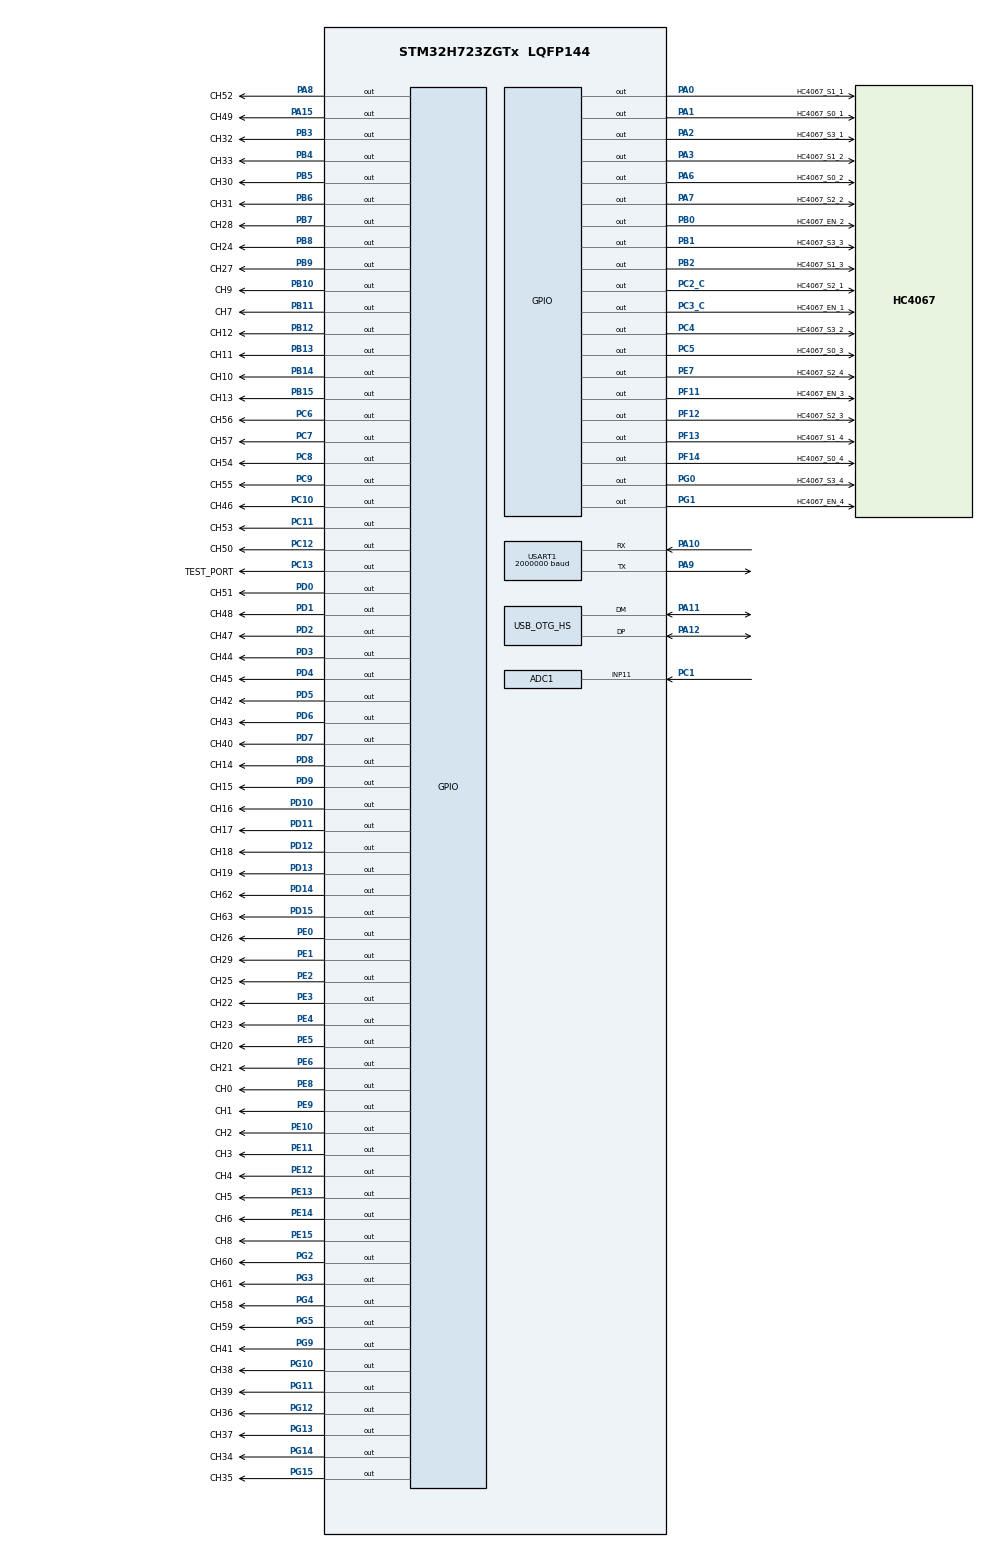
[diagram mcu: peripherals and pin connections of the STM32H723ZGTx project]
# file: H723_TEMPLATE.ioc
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ADC1.Channel-0\#ChannelRegularConversion=ADC_CHANNEL_11
ADC1.ContinuousConvMode=ENABLE
ADC1.ConversionDataManagement=ADC_CONVERSIONDATA_DMA_ONESHOT
ADC1.NbrOfConversionFlag=1
ADC1.OffsetNumber-0\#ChannelRegularConversion=ADC_OFFSET_NONE
ADC1.OffsetSignedSaturation-0\#ChannelRegularConversion=DISABLE
ADC1.Rank-0\#ChannelRegularConversion=1
ADC1.Resolution=ADC_RESOLUTION_8B
ADC1.SamplingTime-0\#ChannelRegularConversion=ADC_SAMPLETIME_1CYCLE_5
ADC1.master=1
CORTEX_M7.default_mode_Activation=1
Dma.ADC1.2.Direction=DMA_PERIPH_TO_MEMORY
Dma.ADC1.2.EventEnable=DISABLE
Dma.ADC1.2.FIFOMode=DMA_FIFOMODE_DISABLE
Dma.ADC1.2.Instance=DMA1_Stream1
Dma.ADC1.2.MemDataAlignment=DMA_MDATAALIGN_BYTE
Dma.ADC1.2.MemInc=DMA_MINC_ENABLE
Dma.ADC1.2.Mode=DMA_NORMAL
Dma.ADC1.2.PeriphDataAlignment=DMA_PDATAALIGN_BYTE
Dma.ADC1.2.PeriphInc=DMA_PINC_DISABLE
Dma.ADC1.2.Polarity=HAL_DMAMUX_REQ_GEN_RISING
Dma.ADC1.2.Priority=DMA_PRIORITY_LOW
Dma.ADC1.2.RequestNumber=1
Dma.ADC1.2.SignalID=NONE
Dma.ADC1.2.SyncEnable=DISABLE
Dma.ADC1.2.SyncPolarity=HAL_DMAMUX_SYNC_NO_EVENT
Dma.ADC1.2.SyncRequestNumber=1
Dma.ADC1.2.SyncSignalID=NONE
Dma.Request0=USART1_RX
Dma.Request1=USART1_TX
Dma.Request2=ADC1
Dma.USART1_RX.0.Direction=DMA_PERIPH_TO_MEMORY
Dma.USART1_RX.0.EventEnable=DISABLE
Dma.USART1_RX.0.FIFOMode=DMA_FIFOMODE_DISABLE
Dma.USART1_RX.0.Instance=DMA1_Stream0
Dma.USART1_RX.0.MemDataAlignment=DMA_MDATAALIGN_BYTE
Dma.USART1_RX.0.MemInc=DMA_MINC_ENABLE
Dma.USART1_RX.0.Mode=DMA_NORMAL
Dma.USART1_RX.0.PeriphDataAlignment=DMA_PDATAALIGN_BYTE
Dma.USART1_RX.0.PeriphInc=DMA_PINC_DISABLE
Dma.USART1_RX.0.Polarity=HAL_DMAMUX_REQ_GEN_RISING
Dma.USART1_RX.0.Priority=DMA_PRIORITY_LOW
Dma.USART1_RX.0.RequestNumber=1
Dma.USART1_RX.0.SignalID=NONE
Dma.USART1_RX.0.SyncEnable=DISABLE
Dma.USART1_RX.0.SyncPolarity=HAL_DMAMUX_SYNC_NO_EVENT
Dma.USART1_RX.0.SyncRequestNumber=1
Dma.USART1_RX.0.SyncSignalID=NONE
Dma.USART1_TX.1.Direction=DMA_MEMORY_TO_PERIPH
Dma.USART1_TX.1.EventEnable=DISABLE
Dma.USART1_TX.1.FIFOMode=DMA_FIFOMODE_DISABLE
Dma.USART1_TX.1.Instance=DMA2_Stream7
Dma.USART1_TX.1.MemDataAlignment=DMA_MDATAALIGN_BYTE
Dma.USART1_TX.1.MemInc=DMA_MINC_ENABLE
Dma.USART1_TX.1.Mode=DMA_NORMAL
Dma.USART1_TX.1.PeriphDataAlignment=DMA_PDATAALIGN_BYTE
Dma.USART1_TX.1.PeriphInc=DMA_PINC_DISABLE
Dma.USART1_TX.1.Polarity=HAL_DMAMUX_REQ_GEN_RISING
Dma.USART1_TX.1.Priority=DMA_PRIORITY_MEDIUM
Dma.USART1_TX.1.RequestNumber=1
Dma.USART1_TX.1.SignalID=NONE
Dma.USART1_TX.1.SyncEnable=DISABLE
Dma.USART1_TX.1.SyncPolarity=HAL_DMAMUX_SYNC_NO_EVENT
Dma.USART1_TX.1.SyncRequestNumber=1
Dma.USART1_TX.1.SyncSignalID=NONE
Mcu.Family=STM32H7
Mcu.Name=STM32H723ZGTx
Mcu.Package=LQFP144
NVIC.DMA1_Stream0_IRQn=true\:0\:0\:false\:false\:true\:false\:true\:true
NVIC.DMA1_Stream1_IRQn=true\:0\:0\:false\:false\:true\:false\:true\:true
NVIC.DMA2_Stream7_IRQn=true\:0\:0\:false\:false\:true\:false\:true\:true
NVIC.OTG_HS_IRQn=true\:0\:0\:false\:false\:true\:false\:true\:true
NVIC.PriorityGroup=NVIC_PRIORITYGROUP_4
NVIC.USART1_IRQn=true\:0\:0\:false\:false\:true\:false\:true\:true
PA0.GPIO_Label=HC4067_S1_1
PA0.GPIO_ModeDefaultOutputPP=GPIO_MODE_OUTPUT_PP
PA0.GPIO_PuPd=GPIO_NOPULL
PA0.GPIO_Speed=GPIO_SPEED_FREQ_VERY_HIGH
PA0.PinState=GPIO_PIN_SET
PA0.Signal=GPIO_Output
PA1.GPIO_Label=HC4067_S0_1
PA1.GPIO_ModeDefaultOutputPP=GPIO_MODE_OUTPUT_PP
PA1.GPIO_PuPd=GPIO_NOPULL
PA1.GPIO_Speed=GPIO_SPEED_FREQ_VERY_HIGH
PA1.PinState=GPIO_PIN_SET
PA1.Signal=GPIO_Output
PA10.Mode=Asynchronous
PA10.Signal=USART1_RX
PA11.Mode=Device_Only_FS
PA11.Signal=USB_OTG_HS_DM
PA12.Mode=Device_Only_FS
PA12.Signal=USB_OTG_HS_DP
PA13(JTMS/SWDIO).Mode=Serial_Wire
PA13(JTMS/SWDIO).Signal=DEBUG_JTMS-SWDIO
PA14(JTCK/SWCLK).Mode=Serial_Wire
PA14(JTCK/SWCLK).Signal=DEBUG_JTCK-SWCLK
PA15(JTDI).GPIO_Label=CH49
PA15(JTDI).GPIO_ModeDefaultOutputPP=GPIO_MODE_OUTPUT_PP
PA15(JTDI).GPIO_PuPd=GPIO_NOPULL
PA15(JTDI).GPIO_Speed=GPIO_SPEED_FREQ_VERY_HIGH
PA15(JTDI).PinState=GPIO_PIN_RESET
PA15(JTDI).Signal=GPIO_Output
PA2.GPIO_Label=HC4067_S3_1
PA2.GPIO_ModeDefaultOutputPP=GPIO_MODE_OUTPUT_PP
PA2.GPIO_PuPd=GPIO_NOPULL
PA2.GPIO_Speed=GPIO_SPEED_FREQ_VERY_HIGH
PA2.PinState=GPIO_PIN_SET
PA2.Signal=GPIO_Output
PA3.GPIO_Label=HC4067_S1_2
PA3.GPIO_ModeDefaultOutputPP=GPIO_MODE_OUTPUT_PP
PA3.GPIO_PuPd=GPIO_NOPULL
PA3.GPIO_Speed=GPIO_SPEED_FREQ_VERY_HIGH
PA3.PinState=GPIO_PIN_SET
PA3.Signal=GPIO_Output
PA6.GPIO_Label=HC4067_S0_2
PA6.GPIO_ModeDefaultOutputPP=GPIO_MODE_OUTPUT_PP
PA6.GPIO_PuPd=GPIO_NOPULL
PA6.GPIO_Speed=GPIO_SPEED_FREQ_VERY_HIGH
PA6.PinState=GPIO_PIN_SET
PA6.Signal=GPIO_Output
PA7.GPIO_Label=HC4067_S2_2
PA7.GPIO_ModeDefaultOutputPP=GPIO_MODE_OUTPUT_PP
PA7.GPIO_PuPd=GPIO_NOPULL
PA7.GPIO_Speed=GPIO_SPEED_FREQ_VERY_HIGH
PA7.PinState=GPIO_PIN_SET
PA7.Signal=GPIO_Output
PA8.GPIO_Label=CH52
PA8.GPIO_ModeDefaultOutputPP=GPIO_MODE_OUTPUT_PP
PA8.GPIO_PuPd=GPIO_NOPULL
PA8.GPIO_Speed=GPIO_SPEED_FREQ_VERY_HIGH
PA8.PinState=GPIO_PIN_RESET
PA8.Signal=GPIO_Output
PA9.Mode=Asynchronous
PA9.Signal=USART1_TX
PB0.GPIO_Label=HC4067_EN_2
PB0.GPIO_ModeDefaultOutputPP=GPIO_MODE_OUTPUT_PP
PB0.GPIO_PuPd=GPIO_NOPULL
PB0.GPIO_Speed=GPIO_SPEED_FREQ_VERY_HIGH
PB0.PinState=GPIO_PIN_SET
PB0.Signal=GPIO_Output
PB1.GPIO_Label=HC4067_S3_3
PB1.GPIO_ModeDefaultOutputPP=GPIO_MODE_OUTPUT_PP
PB1.GPIO_PuPd=GPIO_NOPULL
PB1.GPIO_Speed=GPIO_SPEED_FREQ_VERY_HIGH
PB1.PinState=GPIO_PIN_SET
PB1.Signal=GPIO_Output
PB10.GPIO_Label=CH9
PB10.GPIO_ModeDefaultOutputPP=GPIO_MODE_OUTPUT_PP
PB10.GPIO_PuPd=GPIO_NOPULL
PB10.GPIO_Speed=GPIO_SPEED_FREQ_VERY_HIGH
PB10.PinState=GPIO_PIN_RESET
PB10.Signal=GPIO_Output
PB11.GPIO_Label=CH7
PB11.GPIO_ModeDefaultOutputPP=GPIO_MODE_OUTPUT_PP
PB11.GPIO_PuPd=GPIO_NOPULL
PB11.GPIO_Speed=GPIO_SPEED_FREQ_VERY_HIGH
PB11.PinState=GPIO_PIN_RESET
PB11.Signal=GPIO_Output
PB12.GPIO_Label=CH12
PB12.GPIO_ModeDefaultOutputPP=GPIO_MODE_OUTPUT_PP
PB12.GPIO_PuPd=GPIO_NOPULL
PB12.GPIO_Speed=GPIO_SPEED_FREQ_VERY_HIGH
PB12.PinState=GPIO_PIN_RESET
PB12.Signal=GPIO_Output
PB13.GPIO_Label=CH11
PB13.GPIO_ModeDefaultOutputPP=GPIO_MODE_OUTPUT_PP
PB13.GPIO_PuPd=GPIO_NOPULL
PB13.GPIO_Speed=GPIO_SPEED_FREQ_VERY_HIGH
PB13.PinState=GPIO_PIN_RESET
PB13.Signal=GPIO_Output
PB14.GPIO_Label=CH10
PB14.GPIO_ModeDefaultOutputPP=GPIO_MODE_OUTPUT_PP
PB14.GPIO_PuPd=GPIO_NOPULL
PB14.GPIO_Speed=GPIO_SPEED_FREQ_VERY_HIGH
PB14.PinState=GPIO_PIN_RESET
PB14.Signal=GPIO_Output
PB15.GPIO_Label=CH13
PB15.GPIO_ModeDefaultOutputPP=GPIO_MODE_OUTPUT_PP
PB15.GPIO_PuPd=GPIO_NOPULL
PB15.GPIO_Speed=GPIO_SPEED_FREQ_VERY_HIGH
PB15.PinState=GPIO_PIN_RESET
PB15.Signal=GPIO_Output
PB2.GPIO_Label=HC4067_S1_3
PB2.GPIO_ModeDefaultOutputPP=GPIO_MODE_OUTPUT_PP
PB2.GPIO_PuPd=GPIO_NOPULL
PB2.GPIO_Speed=GPIO_SPEED_FREQ_VERY_HIGH
PB2.PinState=GPIO_PIN_SET
PB2.Signal=GPIO_Output
PB3(JTDO/TRACESWO).GPIO_Label=CH32
PB3(JTDO/TRACESWO).GPIO_ModeDefaultOutputPP=GPIO_MODE_OUTPUT_PP
PB3(JTDO/TRACESWO).GPIO_PuPd=GPIO_NOPULL
PB3(JTDO/TRACESWO).GPIO_Speed=GPIO_SPEED_FREQ_VERY_HIGH
PB3(JTDO/TRACESWO).PinState=GPIO_PIN_RESET
PB3(JTDO/TRACESWO).Signal=GPIO_Output
PB4(NJTRST).GPIO_Label=CH33
PB4(NJTRST).GPIO_ModeDefaultOutputPP=GPIO_MODE_OUTPUT_PP
PB4(NJTRST).GPIO_PuPd=GPIO_NOPULL
PB4(NJTRST).GPIO_Speed=GPIO_SPEED_FREQ_VERY_HIGH
PB4(NJTRST).PinState=GPIO_PIN_RESET
PB4(NJTRST).Signal=GPIO_Output
PB5.GPIO_Label=CH30
PB5.GPIO_ModeDefaultOutputPP=GPIO_MODE_OUTPUT_PP
PB5.GPIO_PuPd=GPIO_NOPULL
PB5.GPIO_Speed=GPIO_SPEED_FREQ_VERY_HIGH
PB5.PinState=GPIO_PIN_RESET
PB5.Signal=GPIO_Output
PB6.GPIO_Label=CH31
PB6.GPIO_ModeDefaultOutputPP=GPIO_MODE_OUTPUT_PP
PB6.GPIO_PuPd=GPIO_NOPULL
PB6.GPIO_Speed=GPIO_SPEED_FREQ_VERY_HIGH
PB6.PinState=GPIO_PIN_RESET
PB6.Signal=GPIO_Output
PB7.GPIO_Label=CH28
PB7.GPIO_ModeDefaultOutputPP=GPIO_MODE_OUTPUT_PP
PB7.GPIO_PuPd=GPIO_NOPULL
PB7.GPIO_Speed=GPIO_SPEED_FREQ_VERY_HIGH
PB7.PinState=GPIO_PIN_RESET
PB7.Signal=GPIO_Output
PB8.GPIO_Label=CH24
PB8.GPIO_ModeDefaultOutputPP=GPIO_MODE_OUTPUT_PP
PB8.GPIO_PuPd=GPIO_NOPULL
PB8.GPIO_Speed=GPIO_SPEED_FREQ_VERY_HIGH
PB8.PinState=GPIO_PIN_RESET
PB8.Signal=GPIO_Output
PB9.GPIO_Label=CH27
PB9.GPIO_ModeDefaultOutputPP=GPIO_MODE_OUTPUT_PP
PB9.GPIO_PuPd=GPIO_NOPULL
PB9.GPIO_Speed=GPIO_SPEED_FREQ_VERY_HIGH
PB9.PinState=GPIO_PIN_RESET
PB9.Signal=GPIO_Output
PC1.Signal=ADCx_INP11
PC10.GPIO_Label=CH46
PC10.GPIO_ModeDefaultOutputPP=GPIO_MODE_OUTPUT_PP
PC10.GPIO_PuPd=GPIO_NOPULL
PC10.GPIO_Speed=GPIO_SPEED_FREQ_VERY_HIGH
PC10.PinState=GPIO_PIN_RESET
PC10.Signal=GPIO_Output
PC11.GPIO_Label=CH53
PC11.GPIO_ModeDefaultOutputPP=GPIO_MODE_OUTPUT_PP
PC11.GPIO_PuPd=GPIO_NOPULL
PC11.GPIO_Speed=GPIO_SPEED_FREQ_VERY_HIGH
PC11.PinState=GPIO_PIN_RESET
PC11.Signal=GPIO_Output
PC12.GPIO_Label=CH50
PC12.GPIO_ModeDefaultOutputPP=GPIO_MODE_OUTPUT_PP
PC12.GPIO_PuPd=GPIO_NOPULL
PC12.GPIO_Speed=GPIO_SPEED_FREQ_VERY_HIGH
PC12.PinState=GPIO_PIN_RESET
PC12.Signal=GPIO_Output
PC13.GPIO_Label=TEST_PORT
PC13.Signal=GPIO_Output
PC2_C.GPIO_Label=HC4067_S2_1
PC2_C.GPIO_ModeDefaultOutputPP=GPIO_MODE_OUTPUT_PP
PC2_C.GPIO_PuPd=GPIO_NOPULL
PC2_C.GPIO_Speed=GPIO_SPEED_FREQ_VERY_HIGH
PC2_C.PinState=GPIO_PIN_SET
PC2_C.Signal=GPIO_Output
PC3_C.GPIO_Label=HC4067_EN_1
PC3_C.GPIO_ModeDefaultOutputPP=GPIO_MODE_OUTPUT_PP
PC3_C.GPIO_PuPd=GPIO_NOPULL
PC3_C.GPIO_Speed=GPIO_SPEED_FREQ_VERY_HIGH
PC3_C.PinState=GPIO_PIN_SET
PC3_C.Signal=GPIO_Output
PC4.GPIO_Label=HC4067_S3_2
PC4.GPIO_ModeDefaultOutputPP=GPIO_MODE_OUTPUT_PP
PC4.GPIO_PuPd=GPIO_NOPULL
PC4.GPIO_Speed=GPIO_SPEED_FREQ_VERY_HIGH
PC4.PinState=GPIO_PIN_SET
PC4.Signal=GPIO_Output
PC5.GPIO_Label=HC4067_S0_3
PC5.GPIO_ModeDefaultOutputPP=GPIO_MODE_OUTPUT_PP
PC5.GPIO_PuPd=GPIO_NOPULL
PC5.GPIO_Speed=GPIO_SPEED_FREQ_VERY_HIGH
PC5.PinState=GPIO_PIN_SET
PC5.Signal=GPIO_Output
PC6.GPIO_Label=CH56
PC6.GPIO_ModeDefaultOutputPP=GPIO_MODE_OUTPUT_PP
PC6.GPIO_PuPd=GPIO_NOPULL
PC6.GPIO_Speed=GPIO_SPEED_FREQ_VERY_HIGH
PC6.PinState=GPIO_PIN_RESET
PC6.Signal=GPIO_Output
PC7.GPIO_Label=CH57
PC7.GPIO_ModeDefaultOutputPP=GPIO_MODE_OUTPUT_PP
PC7.GPIO_PuPd=GPIO_NOPULL
PC7.GPIO_Speed=GPIO_SPEED_FREQ_VERY_HIGH
PC7.PinState=GPIO_PIN_RESET
PC7.Signal=GPIO_Output
PC8.GPIO_Label=CH54
PC8.GPIO_ModeDefaultOutputPP=GPIO_MODE_OUTPUT_PP
PC8.GPIO_PuPd=GPIO_NOPULL
PC8.GPIO_Speed=GPIO_SPEED_FREQ_VERY_HIGH
PC8.PinState=GPIO_PIN_RESET
PC8.Signal=GPIO_Output
PC9.GPIO_Label=CH55
PC9.GPIO_ModeDefaultOutputPP=GPIO_MODE_OUTPUT_PP
PC9.GPIO_PuPd=GPIO_NOPULL
PC9.GPIO_Speed=GPIO_SPEED_FREQ_VERY_HIGH
PC9.PinState=GPIO_PIN_RESET
PC9.Signal=GPIO_Output
PD0.GPIO_Label=CH51
PD0.GPIO_ModeDefaultOutputPP=GPIO_MODE_OUTPUT_PP
PD0.GPIO_PuPd=GPIO_NOPULL
PD0.GPIO_Speed=GPIO_SPEED_FREQ_VERY_HIGH
PD0.PinState=GPIO_PIN_RESET
PD0.Signal=GPIO_Output
PD1.GPIO_Label=CH48
PD1.GPIO_ModeDefaultOutputPP=GPIO_MODE_OUTPUT_PP
PD1.GPIO_PuPd=GPIO_NOPULL
PD1.GPIO_Speed=GPIO_SPEED_FREQ_VERY_HIGH
PD1.PinState=GPIO_PIN_RESET
PD1.Signal=GPIO_Output
PD10.GPIO_Label=CH16
PD10.GPIO_ModeDefaultOutputPP=GPIO_MODE_OUTPUT_PP
PD10.GPIO_PuPd=GPIO_NOPULL
PD10.GPIO_Speed=GPIO_SPEED_FREQ_VERY_HIGH
PD10.PinState=GPIO_PIN_RESET
PD10.Signal=GPIO_Output
PD11.GPIO_Label=CH17
PD11.GPIO_ModeDefaultOutputPP=GPIO_MODE_OUTPUT_PP
PD11.GPIO_PuPd=GPIO_NOPULL
PD11.GPIO_Speed=GPIO_SPEED_FREQ_VERY_HIGH
PD11.PinState=GPIO_PIN_RESET
PD11.Signal=GPIO_Output
PD12.GPIO_Label=CH18
PD12.GPIO_ModeDefaultOutputPP=GPIO_MODE_OUTPUT_PP
PD12.GPIO_PuPd=GPIO_NOPULL
PD12.GPIO_Speed=GPIO_SPEED_FREQ_VERY_HIGH
PD12.PinState=GPIO_PIN_RESET
PD12.Signal=GPIO_Output
PD13.GPIO_Label=CH19
PD13.GPIO_ModeDefaultOutputPP=GPIO_MODE_OUTPUT_PP
PD13.GPIO_PuPd=GPIO_NOPULL
PD13.GPIO_Speed=GPIO_SPEED_FREQ_VERY_HIGH
PD13.PinState=GPIO_PIN_RESET
PD13.Signal=GPIO_Output
PD14.GPIO_Label=CH62
PD14.GPIO_ModeDefaultOutputPP=GPIO_MODE_OUTPUT_PP
PD14.GPIO_PuPd=GPIO_NOPULL
PD14.GPIO_Speed=GPIO_SPEED_FREQ_VERY_HIGH
PD14.PinState=GPIO_PIN_RESET
PD14.Signal=GPIO_Output
PD15.GPIO_Label=CH63
PD15.GPIO_ModeDefaultOutputPP=GPIO_MODE_OUTPUT_PP
PD15.GPIO_PuPd=GPIO_NOPULL
PD15.GPIO_Speed=GPIO_SPEED_FREQ_VERY_HIGH
PD15.PinState=GPIO_PIN_RESET
PD15.Signal=GPIO_Output
PD2.GPIO_Label=CH47
PD2.GPIO_ModeDefaultOutputPP=GPIO_MODE_OUTPUT_PP
PD2.GPIO_PuPd=GPIO_NOPULL
PD2.GPIO_Speed=GPIO_SPEED_FREQ_VERY_HIGH
PD2.PinState=GPIO_PIN_RESET
PD2.Signal=GPIO_Output
PD3.GPIO_Label=CH44
PD3.GPIO_ModeDefaultOutputPP=GPIO_MODE_OUTPUT_PP
PD3.GPIO_PuPd=GPIO_NOPULL
PD3.GPIO_Speed=GPIO_SPEED_FREQ_VERY_HIGH
PD3.PinState=GPIO_PIN_RESET
PD3.Signal=GPIO_Output
PD4.GPIO_Label=CH45
PD4.GPIO_ModeDefaultOutputPP=GPIO_MODE_OUTPUT_PP
PD4.GPIO_PuPd=GPIO_NOPULL
PD4.GPIO_Speed=GPIO_SPEED_FREQ_VERY_HIGH
PD4.PinState=GPIO_PIN_RESET
PD4.Signal=GPIO_Output
PD5.GPIO_Label=CH42
PD5.GPIO_ModeDefaultOutputPP=GPIO_MODE_OUTPUT_PP
PD5.GPIO_PuPd=GPIO_NOPULL
PD5.GPIO_Speed=GPIO_SPEED_FREQ_VERY_HIGH
PD5.PinState=GPIO_PIN_RESET
PD5.Signal=GPIO_Output
PD6.GPIO_Label=CH43
PD6.GPIO_ModeDefaultOutputPP=GPIO_MODE_OUTPUT_PP
PD6.GPIO_PuPd=GPIO_NOPULL
PD6.GPIO_Speed=GPIO_SPEED_FREQ_VERY_HIGH
PD6.PinState=GPIO_PIN_RESET
PD6.Signal=GPIO_Output
PD7.GPIO_Label=CH40
PD7.GPIO_ModeDefaultOutputPP=GPIO_MODE_OUTPUT_PP
PD7.GPIO_PuPd=GPIO_NOPULL
PD7.GPIO_Speed=GPIO_SPEED_FREQ_VERY_HIGH
PD7.PinState=GPIO_PIN_RESET
PD7.Signal=GPIO_Output
PD8.GPIO_Label=CH14
PD8.GPIO_ModeDefaultOutputPP=GPIO_MODE_OUTPUT_PP
PD8.GPIO_PuPd=GPIO_NOPULL
PD8.GPIO_Speed=GPIO_SPEED_FREQ_VERY_HIGH
PD8.PinState=GPIO_PIN_RESET
PD8.Signal=GPIO_Output
PD9.GPIO_Label=CH15
PD9.GPIO_ModeDefaultOutputPP=GPIO_MODE_OUTPUT_PP
PD9.GPIO_PuPd=GPIO_NOPULL
PD9.GPIO_Speed=GPIO_SPEED_FREQ_VERY_HIGH
PD9.PinState=GPIO_PIN_RESET
PD9.Signal=GPIO_Output
PE0.GPIO_Label=CH26
PE0.GPIO_ModeDefaultOutputPP=GPIO_MODE_OUTPUT_PP
PE0.GPIO_PuPd=GPIO_NOPULL
PE0.GPIO_Speed=GPIO_SPEED_FREQ_VERY_HIGH
PE0.PinState=GPIO_PIN_RESET
PE0.Signal=GPIO_Output
PE1.GPIO_Label=CH29
PE1.GPIO_ModeDefaultOutputPP=GPIO_MODE_OUTPUT_PP
PE1.GPIO_PuPd=GPIO_NOPULL
PE1.GPIO_Speed=GPIO_SPEED_FREQ_VERY_HIGH
PE1.PinState=GPIO_PIN_RESET
PE1.Signal=GPIO_Output
PE10.GPIO_Label=CH2
PE10.GPIO_ModeDefaultOutputPP=GPIO_MODE_OUTPUT_PP
PE10.GPIO_PuPd=GPIO_NOPULL
PE10.GPIO_Speed=GPIO_SPEED_FREQ_VERY_HIGH
PE10.PinState=GPIO_PIN_RESET
PE10.Signal=GPIO_Output
PE11.GPIO_Label=CH3
PE11.GPIO_ModeDefaultOutputPP=GPIO_MODE_OUTPUT_PP
PE11.GPIO_PuPd=GPIO_NOPULL
PE11.GPIO_Speed=GPIO_SPEED_FREQ_VERY_HIGH
PE11.PinState=GPIO_PIN_RESET
PE11.Signal=GPIO_Output
PE12.GPIO_Label=CH4
PE12.GPIO_ModeDefaultOutputPP=GPIO_MODE_OUTPUT_PP
PE12.GPIO_PuPd=GPIO_NOPULL
PE12.GPIO_Speed=GPIO_SPEED_FREQ_VERY_HIGH
PE12.PinState=GPIO_PIN_RESET
PE12.Signal=GPIO_Output
PE13.GPIO_Label=CH5
PE13.GPIO_ModeDefaultOutputPP=GPIO_MODE_OUTPUT_PP
PE13.GPIO_PuPd=GPIO_NOPULL
PE13.GPIO_Speed=GPIO_SPEED_FREQ_VERY_HIGH
PE13.PinState=GPIO_PIN_RESET
PE13.Signal=GPIO_Output
PE14.GPIO_Label=CH6
PE14.GPIO_ModeDefaultOutputPP=GPIO_MODE_OUTPUT_PP
PE14.GPIO_PuPd=GPIO_NOPULL
PE14.GPIO_Speed=GPIO_SPEED_FREQ_VERY_HIGH
PE14.PinState=GPIO_PIN_RESET
PE14.Signal=GPIO_Output
PE15.GPIO_Label=CH8
PE15.GPIO_ModeDefaultOutputPP=GPIO_MODE_OUTPUT_PP
PE15.GPIO_PuPd=GPIO_NOPULL
PE15.GPIO_Speed=GPIO_SPEED_FREQ_VERY_HIGH
PE15.PinState=GPIO_PIN_RESET
PE15.Signal=GPIO_Output
PE2.GPIO_Label=CH25
PE2.GPIO_Speed=GPIO_SPEED_FREQ_VERY_HIGH
PE2.Signal=GPIO_Output
PE3.GPIO_Label=CH22
PE3.GPIO_ModeDefaultOutputPP=GPIO_MODE_OUTPUT_PP
PE3.GPIO_PuPd=GPIO_NOPULL
PE3.GPIO_Speed=GPIO_SPEED_FREQ_VERY_HIGH
PE3.PinState=GPIO_PIN_RESET
PE3.Signal=GPIO_Output
PE4.GPIO_Label=CH23
PE4.GPIO_ModeDefaultOutputPP=GPIO_MODE_OUTPUT_PP
PE4.GPIO_PuPd=GPIO_NOPULL
PE4.GPIO_Speed=GPIO_SPEED_FREQ_VERY_HIGH
PE4.PinState=GPIO_PIN_RESET
PE4.Signal=GPIO_Output
PE5.GPIO_Label=CH20
PE5.GPIO_ModeDefaultOutputPP=GPIO_MODE_OUTPUT_PP
PE5.GPIO_PuPd=GPIO_NOPULL
PE5.GPIO_Speed=GPIO_SPEED_FREQ_VERY_HIGH
PE5.PinState=GPIO_PIN_RESET
PE5.Signal=GPIO_Output
PE6.GPIO_Label=CH21
PE6.GPIO_ModeDefaultOutputPP=GPIO_MODE_OUTPUT_PP
PE6.GPIO_PuPd=GPIO_NOPULL
PE6.GPIO_Speed=GPIO_SPEED_FREQ_VERY_HIGH
PE6.PinState=GPIO_PIN_RESET
PE6.Signal=GPIO_Output
PE7.GPIO_Label=HC4067_S2_4
PE7.GPIO_Speed=GPIO_SPEED_FREQ_VERY_HIGH
PE7.PinState=GPIO_PIN_SET
PE7.Signal=GPIO_Output
PE8.GPIO_Label=CH0
PE8.GPIO_ModeDefaultOutputPP=GPIO_MODE_OUTPUT_PP
PE8.GPIO_PuPd=GPIO_NOPULL
PE8.GPIO_Speed=GPIO_SPEED_FREQ_VERY_HIGH
PE8.PinState=GPIO_PIN_RESET
PE8.Signal=GPIO_Output
PE9.GPIO_Label=CH1
PE9.GPIO_ModeDefaultOutputPP=GPIO_MODE_OUTPUT_PP
PE9.GPIO_PuPd=GPIO_NOPULL
PE9.GPIO_Speed=GPIO_SPEED_FREQ_VERY_HIGH
PE9.PinState=GPIO_PIN_RESET
PE9.Signal=GPIO_Output
PF11.GPIO_Label=HC4067_EN_3
PF11.GPIO_ModeDefaultOutputPP=GPIO_MODE_OUTPUT_PP
PF11.GPIO_PuPd=GPIO_NOPULL
PF11.GPIO_Speed=GPIO_SPEED_FREQ_VERY_HIGH
PF11.PinState=GPIO_PIN_SET
PF11.Signal=GPIO_Output
PF12.GPIO_Label=HC4067_S2_3
PF12.GPIO_ModeDefaultOutputPP=GPIO_MODE_OUTPUT_PP
PF12.GPIO_PuPd=GPIO_NOPULL
PF12.GPIO_Speed=GPIO_SPEED_FREQ_VERY_HIGH
PF12.PinState=GPIO_PIN_SET
PF12.Signal=GPIO_Output
PF13.GPIO_Label=HC4067_S1_4
PF13.GPIO_ModeDefaultOutputPP=GPIO_MODE_OUTPUT_PP
PF13.GPIO_PuPd=GPIO_NOPULL
PF13.GPIO_Speed=GPIO_SPEED_FREQ_VERY_HIGH
PF13.PinState=GPIO_PIN_SET
PF13.Signal=GPIO_Output
PF14.GPIO_Label=HC4067_S0_4
PF14.GPIO_ModeDefaultOutputPP=GPIO_MODE_OUTPUT_PP
PF14.GPIO_PuPd=GPIO_NOPULL
PF14.GPIO_Speed=GPIO_SPEED_FREQ_VERY_HIGH
PF14.PinState=GPIO_PIN_SET
PF14.Signal=GPIO_Output
PG0.GPIO_Label=HC4067_S3_4
PG0.GPIO_ModeDefaultOutputPP=GPIO_MODE_OUTPUT_PP
PG0.GPIO_PuPd=GPIO_NOPULL
PG0.GPIO_Speed=GPIO_SPEED_FREQ_VERY_HIGH
PG0.PinState=GPIO_PIN_SET
PG0.Signal=GPIO_Output
PG1.GPIO_Label=HC4067_EN_4
PG1.GPIO_ModeDefaultOutputPP=GPIO_MODE_OUTPUT_PP
PG1.GPIO_PuPd=GPIO_NOPULL
PG1.GPIO_Speed=GPIO_SPEED_FREQ_VERY_HIGH
PG1.PinState=GPIO_PIN_SET
PG1.Signal=GPIO_Output
PG10.GPIO_Label=CH38
PG10.GPIO_ModeDefaultOutputPP=GPIO_MODE_OUTPUT_PP
PG10.GPIO_PuPd=GPIO_NOPULL
PG10.GPIO_Speed=GPIO_SPEED_FREQ_VERY_HIGH
PG10.PinState=GPIO_PIN_RESET
PG10.Signal=GPIO_Output
PG11.GPIO_Label=CH39
PG11.GPIO_ModeDefaultOutputPP=GPIO_MODE_OUTPUT_PP
PG11.GPIO_PuPd=GPIO_NOPULL
PG11.GPIO_Speed=GPIO_SPEED_FREQ_VERY_HIGH
PG11.PinState=GPIO_PIN_RESET
PG11.Signal=GPIO_Output
PG12.GPIO_Label=CH36
PG12.GPIO_ModeDefaultOutputPP=GPIO_MODE_OUTPUT_PP
PG12.GPIO_PuPd=GPIO_NOPULL
PG12.GPIO_Speed=GPIO_SPEED_FREQ_VERY_HIGH
PG12.PinState=GPIO_PIN_RESET
PG12.Signal=GPIO_Output
PG13.GPIO_Label=CH37
PG13.GPIO_ModeDefaultOutputPP=GPIO_MODE_OUTPUT_PP
PG13.GPIO_PuPd=GPIO_NOPULL
PG13.GPIO_Speed=GPIO_SPEED_FREQ_VERY_HIGH
PG13.PinState=GPIO_PIN_RESET
PG13.Signal=GPIO_Output
PG14.GPIO_Label=CH34
PG14.GPIO_ModeDefaultOutputPP=GPIO_MODE_OUTPUT_PP
PG14.GPIO_PuPd=GPIO_NOPULL
PG14.GPIO_Speed=GPIO_SPEED_FREQ_VERY_HIGH
PG14.PinState=GPIO_PIN_RESET
PG14.Signal=GPIO_Output
PG15.GPIO_Label=CH35
PG15.GPIO_ModeDefaultOutputPP=GPIO_MODE_OUTPUT_PP
PG15.GPIO_PuPd=GPIO_NOPULL
PG15.GPIO_Speed=GPIO_SPEED_FREQ_VERY_HIGH
PG15.PinState=GPIO_PIN_RESET
PG15.Signal=GPIO_Output
PG2.GPIO_Label=CH60
PG2.GPIO_ModeDefaultOutputPP=GPIO_MODE_OUTPUT_PP
PG2.GPIO_PuPd=GPIO_NOPULL
PG2.GPIO_Speed=GPIO_SPEED_FREQ_VERY_HIGH
PG2.PinState=GPIO_PIN_RESET
PG2.Signal=GPIO_Output
PG3.GPIO_Label=CH61
PG3.GPIO_ModeDefaultOutputPP=GPIO_MODE_OUTPUT_PP
PG3.GPIO_PuPd=GPIO_NOPULL
PG3.GPIO_Speed=GPIO_SPEED_FREQ_VERY_HIGH
PG3.PinState=GPIO_PIN_RESET
PG3.Signal=GPIO_Output
PG4.GPIO_Label=CH58
PG4.GPIO_ModeDefaultOutputPP=GPIO_MODE_OUTPUT_PP
PG4.GPIO_PuPd=GPIO_NOPULL
PG4.GPIO_Speed=GPIO_SPEED_FREQ_VERY_HIGH
PG4.PinState=GPIO_PIN_RESET
PG4.Signal=GPIO_Output
PG5.GPIO_Label=CH59
PG5.GPIO_ModeDefaultOutputPP=GPIO_MODE_OUTPUT_PP
PG5.GPIO_PuPd=GPIO_NOPULL
PG5.GPIO_Speed=GPIO_SPEED_FREQ_VERY_HIGH
PG5.PinState=GPIO_PIN_RESET
PG5.Signal=GPIO_Output
PG9.GPIO_Label=CH41
PG9.GPIO_ModeDefaultOutputPP=GPIO_MODE_OUTPUT_PP
PG9.GPIO_PuPd=GPIO_NOPULL
PG9.GPIO_Speed=GPIO_SPEED_FREQ_VERY_HIGH
PG9.PinState=GPIO_PIN_RESET
PG9.Signal=GPIO_Output
PH0-OSC_IN.Mode=HSE-External-Oscillator
PH0-OSC_IN.Signal=RCC_OSC_IN
PH1-OSC_OUT.Mode=HSE-External-Oscillator
PH1-OSC_OUT.Signal=RCC_OSC_OUT
ProjectManager.HeapSize=0x200
ProjectManager.StackSize=0x400
ProjectManager.TargetToolchain=MDK-ARM V5.32
RCC.ADCCLockSelection=RCC_ADCCLKSOURCE_PLL3
RCC.ADCFreq_Value=120000000
RCC.APB1Freq_Value=137500000
RCC.APB2Freq_Value=137500000
RCC.APB3Freq_Value=137500000
RCC.APB4Freq_Value=137500000
RCC.CortexFreq_Value=550000000
RCC.D1PPRE=RCC_APB3_DIV2
RCC.D2PPRE1=RCC_APB1_DIV2
RCC.D2PPRE2=RCC_APB2_DIV2
RCC.D3PPRE=RCC_APB4_DIV2
RCC.DIVM1=2
RCC.DIVM2=2
RCC.DIVM3=5
RCC.DIVN1=44
RCC.DIVN2=15
RCC.DIVN3=48
RCC.DIVP1=1
RCC.DIVQ3=5
RCC.HCLKFreq_Value=275000000
RCC.HPRE=RCC_HCLK_DIV2
RCC.PLL2FRACN=0
RCC.PLL3FRACN=0
RCC.PLLFRACN=0
RCC.SYSCLKFreq_VALUE=550000000
RCC.SYSCLKSource=RCC_SYSCLKSOURCE_PLLCLK
RCC.USBCLockSelection=RCC_USBCLKSOURCE_PLL3
RCC.USBFreq_Value=48000000
SH.ADCx_INP11.0=ADC1_INP11,IN11-Single-Ended
USART1.BaudRate=2000000
USART1.VirtualMode-Asynchronous=VM_ASYNC
USB_DEVICE.CLASS_NAME_HS=CDC
USB_DEVICE.VirtualMode=Cdc
USB_DEVICE.VirtualModeHS=Cdc_HS
USB_OTG_HS.VirtualMode-Device_Only_FS=Device_Only_FS
VP_MEMORYMAP_VS_MEMORYMAP.Mode=CurAppReg
VP_USB_DEVICE_VS_USB_DEVICE_CDC_HS.Mode=CDC_HS
board=custom

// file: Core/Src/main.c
/* USER CODE BEGIN Header */
/**
 ******************************************************************************
 * @file           : main.c
 * @brief          : Main program body
 ******************************************************************************
 * @attention
 *
 * Copyright (c) 2025 STMicroelectronics.
 * All rights reserved.
 *
 * This software is licensed under terms that can be found in the LICENSE file
 * in the root directory of this software component.
 * If no LICENSE file comes with this software, it is provided AS-IS.
 *
 ******************************************************************************
 */
/* USER CODE END Header */
#include "main.h"
#include "adc.h"
#include "dma.h"
#include "memorymap.h"
#include "usart.h"
#include "usb_device.h"
#include "gpio.h"

/* USER CODE BEGIN Includes */
#include "user_comm.h"

/* USER CODE END Includes */

void SystemClock_Config(void);
void PeriphCommonClock_Config(void);
static void MPU_Config(void);

/* USER CODE BEGIN 0 */

const uint8_t tx_str[] = "shit\r\n";
uint8_t g_sendbuf[200] = {0}; // DMA发送缓冲区
volatile uint8_t some[10] = {0};
/* USER CODE END 0 */

int main(void)
{

    /* USER CODE BEGIN 1 */
    // enable cache
    SCB_EnableICache(); // Enable instruction cache
    SCB_EnableDCache(); // Enable data cache
    /* USER CODE END 1 */

    /* MPU Configuration--------------------------------------------------------*/
    MPU_Config();

    /* MCU Configuration--------------------------------------------------------*/

    /* Reset of all peripherals, Initializes the Flash interface and the Systick. */
    HAL_Init();

    /* Configure the system clock */
    SystemClock_Config();

    /* Configure the peripherals common clocks */
    PeriphCommonClock_Config();

    /* Initialize all configured peripherals */
    MX_GPIO_Init();
    MX_DMA_Init();
    MX_USART1_UART_Init();
    MX_ADC1_Init();
    MX_USB_DEVICE_Init();
    /* USER CODE BEGIN 2 */
    delay_init(550); // Initialize delay with a clock of 216 MHz

    init_frame_tail();
    // static uint16_t counter = 0;
    // usart_init(120, 115200);
    // mpu_memory_protection();

    // dma_usart_tx_config(DMA2_Stream7, 42, (uint32_t)&USART1->TDR, (uint32_t)g_sendbuf);
    /* USER CODE END 2 */

    /* Infinite loop */
    /* USER CODE BEGIN WHILE */
    while (1)
    {
        // HAL_GPIO_TogglePin(TEST_PORT_GPIO_Port, TEST_PORT_Pin);
        // usb_task();
        // main_task_update();

        main_task();

        // usb_send_data();

        // main_task_adc();
        // main_task_only_ch0();

        // TEST_PORT_UP;
        // TEST_PORT_DOWN;

        //  counter++;
        // delay_ms(1000);
        // dma_enable(DMA2_Stream7, 20);
        // while (1)
        // {
        //     if (DMA2->HISR & (1 << 27)) /* 等待DMA2_Steam7传输完成 */
        //     {
        //         DMA2->HIFCR |= 1 << 27; /* 清除DMA2_Steam7传输完成标志 */
        //         break;
        //     }
        // }
        // printf("Helloworld %d\r\n", counter);
        // memset(tx_buf, 0, sizeof(tx_buf)); // Clear the buffer
        // tx_buf[0] = counter;
        // 下面的是可用的
        // HAL_UART_Transmit(&huart1, tx_buf, sizeof(tx_buf), 1000);
        // 可打印, 但是数据是错的
        // SCB_CleanDCache_by_Addr((uint32_t *)tx_buf, sizeof(tx_buf));
        // HAL_UART_Transmit_DMA(&huart1, tx_buf, 6);

        // USART1->CR3 = 1 << 7; /* 使能串口1的DMA发送 */
        // dma_enable(DMA2_Stream7, SEND_BUF_SIZE); /* 开始一次DMA传输！ */

        // HAL_UART_Transmit_DMA(&huart1, tx_str, 6);

        // delay_ms(1); // Delay for 1000 ms (1 second)
        // HAL_GPIO_TogglePin(TEST_PORT_GPIO_Port, TEST_PORT_Pin); // Toggle GPIO pin PB0
        /* USER CODE END WHILE */

    }
}

void SystemClock_Config(void)
{
    RCC_OscInitTypeDef RCC_OscInitStruct = {0};
    RCC_ClkInitTypeDef RCC_ClkInitStruct = {0};

    /** Supply configuration update enable
     */
    HAL_PWREx_ConfigSupply(PWR_LDO_SUPPLY);

    /** Configure the main internal regulator output voltage
     */
    __HAL_PWR_VOLTAGESCALING_CONFIG(PWR_REGULATOR_VOLTAGE_SCALE0);

    while (!__HAL_PWR_GET_FLAG(PWR_FLAG_VOSRDY))
    {
    }

    /** Initializes the RCC Oscillators according to the specified parameters
     * in the RCC_OscInitTypeDef structure.
     */
    RCC_OscInitStruct.OscillatorType = RCC_OSCILLATORTYPE_HSE;
    RCC_OscInitStruct.HSEState = RCC_HSE_ON;
    RCC_OscInitStruct.PLL.PLLState = RCC_PLL_ON;
    RCC_OscInitStruct.PLL.PLLSource = RCC_PLLSOURCE_HSE;
    RCC_OscInitStruct.PLL.PLLM = 2;
    RCC_OscInitStruct.PLL.PLLN = 44;
    RCC_OscInitStruct.PLL.PLLP = 1;
    RCC_OscInitStruct.PLL.PLLQ = 2;
    RCC_OscInitStruct.PLL.PLLR = 2;
    RCC_OscInitStruct.PLL.PLLRGE = RCC_PLL1VCIRANGE_3;
    RCC_OscInitStruct.PLL.PLLVCOSEL = RCC_PLL1VCOWIDE;
    RCC_OscInitStruct.PLL.PLLFRACN = 0;
    if (HAL_RCC_OscConfig(&RCC_OscInitStruct) != HAL_OK)
    {
        Error_Handler();
    }

    /** Initializes the CPU, AHB and APB buses clocks
     */
    RCC_ClkInitStruct.ClockType = RCC_CLOCKTYPE_HCLK | RCC_CLOCKTYPE_SYSCLK | RCC_CLOCKTYPE_PCLK1 | RCC_CLOCKTYPE_PCLK2 | RCC_CLOCKTYPE_D3PCLK1 | RCC_CLOCKTYPE_D1PCLK1;
    RCC_ClkInitStruct.SYSCLKSource = RCC_SYSCLKSOURCE_PLLCLK;
    RCC_ClkInitStruct.SYSCLKDivider = RCC_SYSCLK_DIV1;
    RCC_ClkInitStruct.AHBCLKDivider = RCC_HCLK_DIV2;
    RCC_ClkInitStruct.APB3CLKDivider = RCC_APB3_DIV2;
    RCC_ClkInitStruct.APB1CLKDivider = RCC_APB1_DIV2;
    RCC_ClkInitStruct.APB2CLKDivider = RCC_APB2_DIV2;
    RCC_ClkInitStruct.APB4CLKDivider = RCC_APB4_DIV2;

    if (HAL_RCC_ClockConfig(&RCC_ClkInitStruct, FLASH_LATENCY_3) != HAL_OK)
    {
        Error_Handler();
    }
}

void PeriphCommonClock_Config(void)
{
    RCC_PeriphCLKInitTypeDef PeriphClkInitStruct = {0};

    /** Initializes the peripherals clock
     */
    PeriphClkInitStruct.PeriphClockSelection = RCC_PERIPHCLK_USB | RCC_PERIPHCLK_ADC;
    PeriphClkInitStruct.PLL3.PLL3M = 5;
    PeriphClkInitStruct.PLL3.PLL3N = 48;
    PeriphClkInitStruct.PLL3.PLL3P = 2;
    PeriphClkInitStruct.PLL3.PLL3Q = 5;
    PeriphClkInitStruct.PLL3.PLL3R = 2;
    PeriphClkInitStruct.PLL3.PLL3RGE = RCC_PLL3VCIRANGE_2;
    PeriphClkInitStruct.PLL3.PLL3VCOSEL = RCC_PLL3VCOWIDE;
    PeriphClkInitStruct.PLL3.PLL3FRACN = 0;
    PeriphClkInitStruct.UsbClockSelection = RCC_USBCLKSOURCE_PLL3;
    PeriphClkInitStruct.AdcClockSelection = RCC_ADCCLKSOURCE_PLL3;
    if (HAL_RCCEx_PeriphCLKConfig(&PeriphClkInitStruct) != HAL_OK)
    {
        Error_Handler();
    }
}

/* USER CODE BEGIN 4 */
void MPU_Config(void)
{
    MPU_Region_InitTypeDef MPU_InitStruct = {0};

    /* Disable the MPU */
    HAL_MPU_Disable();

    /* Region 0: Set whole memory space as NO_ACCESS (default fallback) */
    MPU_InitStruct.Enable = MPU_REGION_ENABLE;
    MPU_InitStruct.Number = MPU_REGION_NUMBER0;
    MPU_InitStruct.BaseAddress = 0x00000000;
    MPU_InitStruct.Size = MPU_REGION_SIZE_4GB;
    MPU_InitStruct.SubRegionDisable = 0x87;
    MPU_InitStruct.TypeExtField = MPU_TEX_LEVEL0;
    MPU_InitStruct.AccessPermission = MPU_REGION_NO_ACCESS;
    MPU_InitStruct.DisableExec = MPU_INSTRUCTION_ACCESS_DISABLE;
    MPU_InitStruct.IsShareable = MPU_ACCESS_SHAREABLE;
    MPU_InitStruct.IsCacheable = MPU_ACCESS_NOT_CACHEABLE;
    MPU_InitStruct.IsBufferable = MPU_ACCESS_NOT_BUFFERABLE;

    HAL_MPU_ConfigRegion(&MPU_InitStruct);

    /* Region 1: Configure 0x30000000~ for DMA buffers (Non-cacheable) */
    MPU_InitStruct.Enable = MPU_REGION_ENABLE;
    MPU_InitStruct.Number = MPU_REGION_NUMBER1;
    MPU_InitStruct.BaseAddress = 0x30000000;
    MPU_InitStruct.Size = MPU_REGION_SIZE_128KB; // 或者根据需要换成 256KB、512KB
    MPU_InitStruct.AccessPermission = MPU_REGION_FULL_ACCESS;
    MPU_InitStruct.IsBufferable = MPU_ACCESS_BUFFERABLE;
    MPU_InitStruct.IsCacheable = MPU_ACCESS_NOT_CACHEABLE;
    MPU_InitStruct.IsShareable = MPU_ACCESS_SHAREABLE;
    MPU_InitStruct.TypeExtField = MPU_TEX_LEVEL0;
    MPU_InitStruct.SubRegionDisable = 0x00;
    MPU_InitStruct.DisableExec = MPU_INSTRUCTION_ACCESS_DISABLE;

    HAL_MPU_ConfigRegion(&MPU_InitStruct);

    /* Enable the MPU */
    HAL_MPU_Enable(MPU_PRIVILEGED_DEFAULT);
}
/* USER CODE END 4 */

/* MPU Configuration */

void MPU_Config_(void)
{
    MPU_Region_InitTypeDef MPU_InitStruct = {0};

    /* Disables the MPU */
    HAL_MPU_Disable();

    /** Initializes and configures the Region and the memory to be protected
     */
    MPU_InitStruct.Enable = MPU_REGION_ENABLE;
    MPU_InitStruct.Number = MPU_REGION_NUMBER0;
    MPU_InitStruct.BaseAddress = 0x0;
    MPU_InitStruct.Size = MPU_REGION_SIZE_4GB;
    MPU_InitStruct.SubRegionDisable = 0x87;
    MPU_InitStruct.TypeExtField = MPU_TEX_LEVEL0;
    MPU_InitStruct.AccessPermission = MPU_REGION_NO_ACCESS;
    MPU_InitStruct.DisableExec = MPU_INSTRUCTION_ACCESS_DISABLE;
    MPU_InitStruct.IsShareable = MPU_ACCESS_SHAREABLE;
    MPU_InitStruct.IsCacheable = MPU_ACCESS_NOT_CACHEABLE;
    MPU_InitStruct.IsBufferable = MPU_ACCESS_NOT_BUFFERABLE;

    HAL_MPU_ConfigRegion(&MPU_InitStruct);
    /* Enables the MPU */
    HAL_MPU_Enable(MPU_PRIVILEGED_DEFAULT);
}

void Error_Handler(void)
{
    __disable_irq();
    while (1)
    {
    }
}
